# DEBUGSS_WRAP_PVIEW_CFG_0_000700002400h register map
Vendor: Texas Instruments
Peripheral module from a debugger description file (folder AM275x).
Registers are 32-bit, read-only, reset 0x0 unless marked. A register's access mark holds for its fields unless they carry their own. Offsets are as the file gives them; lines under a group give offsets from that group; [hi:lo] are bit positions; {n}, {i} and the like mark numbered series; 'fields as' and 'values as' point back to an identical list; <NAME> marks a mode.

## pview_cfg_0
0x00 PVIEW_CFG_0_PVIEW_STATE0 — This register provides the device specific power status. A read of Power View State Register will lock the values for all other Power View State Registers. A read from the last Power View State register will unlock them so they can update
  [31:0] POWER_VIEW_STATE_REG0
0xF0 PVIEW_CFG_0_PVIEW_CAPABILITY — The Capability Register provides information on the number of Power State registers implemented in the AP
  [5:0] NUMSTATREG — The value read indicates the number of valid Power State Registers that are implemented in the system The maximum number is 60 and the minimum number is 1 The registers are always implemented at contiguous addresses so a value of 7 means that registers 0-6 are valid
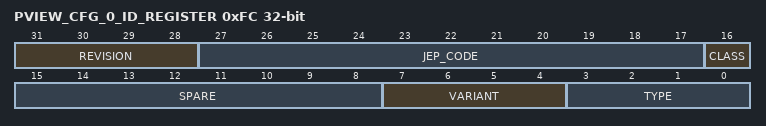
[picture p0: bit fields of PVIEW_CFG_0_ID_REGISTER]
0xFC PVIEW_CFG_0_ID_REGISTER — Reading this register returns the ID information for this AP.
  [31:28] REVISION — Device Revision [0]
  [27:17] JEP_CODE — Device JEP Code [0x017]
  [16] CLASS — Device Class[0] [not a memory access port]
  [15:8] SPARE — Spare, returns 0
  [7:4] VARIANT — Device Variant [0]
  [3:0] TYPE — Device Type = 3
